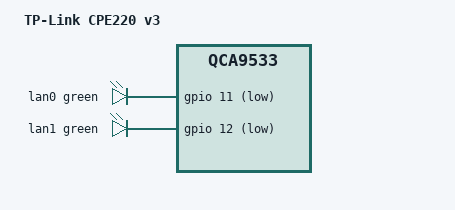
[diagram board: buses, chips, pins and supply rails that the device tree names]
// SPDX-License-Identifier: GPL-2.0-or-later OR MIT
/dts-v1/;

#include "qca9533_tplink_cpexxx.dtsi"

/ {
	compatible = "tplink,cpe220-v3", "qca,qca9533";
	model = "TP-Link CPE220 v3";
};

&leds {
	lan0 {
		function = LED_FUNCTION_LAN;
		function-enumerator = <0>;
		color = <LED_COLOR_ID_GREEN>;
		gpios = <&gpio 11 GPIO_ACTIVE_LOW>;
	};

	lan1 {
		function = LED_FUNCTION_LAN;
		function-enumerator = <1>;
		color = <LED_COLOR_ID_GREEN>;
		gpios = <&gpio 12 GPIO_ACTIVE_LOW>;
	};
};

&eth1 {
	mtd-mac-address = <&info 0x8>;

	gmac-config {
		device = <&gmac>;
		switch-phy-swap = <0>;
		switch-only-mode = <1>;
	};
};
